# OSPI1_OSPI_CFG_53A00000h register map
Vendor: Texas Instruments
Peripheral module from a debugger description file (folder AM261x).
Registers are 32-bit, read-only, reset 0x0 unless marked. A register's access mark holds for its fields unless they carry their own. Offsets are as the file gives them; lines under a group give offsets from that group; [hi:lo] are bit positions; {n}, {i} and the like mark numbered series; 'fields as' and 'values as' point back to an identical list; <NAME> marks a mode.

## OSPI_CFG
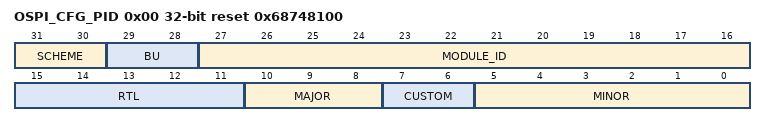
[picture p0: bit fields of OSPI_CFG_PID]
0x00 OSPI_CFG_PID reset 0x68748100 — The Revision Register contains the major and minor revisions for the module.
  [31:30] SCHEME — PID register scheme
  [29:28] BU — Business Unit: 10 = Processors
  [27:16] MODULE_ID
  [15:11] RTL — RTL revision. Will vary depending on release.
  [10:8] MAJOR — Major revision
  [7:6] CUSTOM
  [5:0] MINOR — Minor revision
0x08 OSPI_CFG_STAT — The Status register provide general status bits for the ospi.
  [1] MEM_INIT_DONE — Bit indicates the memory initialization done status of the OSPI SRAM 1:Memory Intialization Done
0x20 OSPI_CFG_EOI wo — End of Interrupt Register.
  [7:0] EOI — Write with bit position of targetted interrupt. (E.g. Ext TS is bit 0).Upon write, level interrupt will clear and if unserviced interrupt counter > 1 will issue another pulse interrupt
